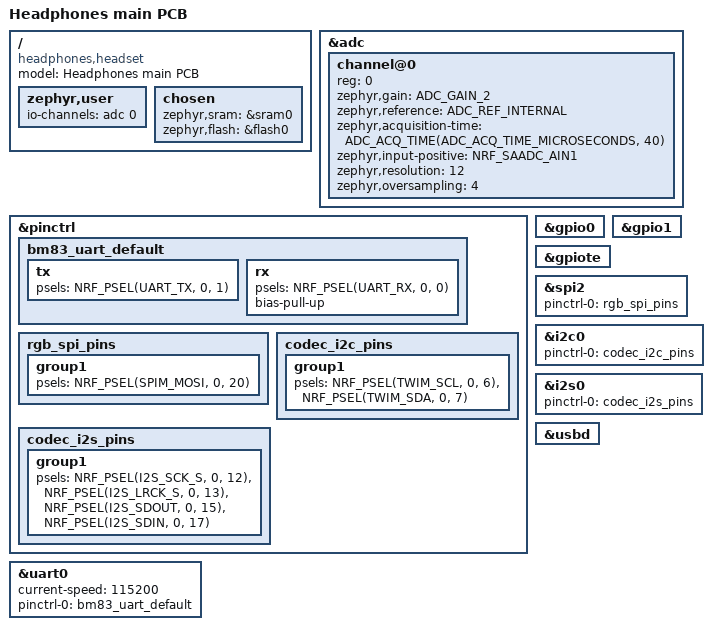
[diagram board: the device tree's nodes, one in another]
/dts-v1/;

#include <nordic/nrf52840_qiaa.dtsi>
#include <zephyr/dt-bindings/adc/adc.h>
#include <zephyr/dt-bindings/adc/nrf-saadc.h>
#include <zephyr/dt-bindings/pinctrl/nrf-pinctrl.h>

/ {
    model = "Headphones main PCB";
    compatible = "headphones,headset";

    zephyr,user {
        io-channels = <&adc 0>;
    };

    chosen {
        zephyr,sram = &sram0;
        zephyr,flash = &flash0;
    };
};

&adc {
    status = "okay";
    #address-cells = <1>;
    #size-cells = <0>;

    channel@0 {
        reg = <0>;
        zephyr,gain = "ADC_GAIN_2";
        zephyr,reference = "ADC_REF_INTERNAL";
        zephyr,acquisition-time = <ADC_ACQ_TIME(ADC_ACQ_TIME_MICROSECONDS, 40)>;
        zephyr,input-positive = <NRF_SAADC_AIN1>;
        zephyr,resolution = <12>;
        zephyr,oversampling = <4>;
    };
};

&pinctrl {
    bm83_uart_default: bm83_uart_default {
        tx {
            psels = <NRF_PSEL(UART_TX, 0, 1)>;
        };
        rx {
            psels = <NRF_PSEL(UART_RX, 0, 0)>;
            bias-pull-up;
        };
    };
    rgb_spi_pins: rgb_spi_pins {
        group1 {
            psels = <NRF_PSEL(SPIM_MOSI, 0, 20)>;
        };
    };
    codec_i2c_pins: codec_i2c_pins {
        group1 {
            psels = <NRF_PSEL(TWIM_SCL, 0, 6)>,
                    <NRF_PSEL(TWIM_SDA, 0, 7)>;
        };
    };
    codec_i2s_pins: codec_i2s_pins {
        group1 {
            psels = <NRF_PSEL(I2S_SCK_S, 0, 12)>,
                    <NRF_PSEL(I2S_LRCK_S, 0, 13)>,
                    <NRF_PSEL(I2S_SDOUT, 0, 15)>,
                    <NRF_PSEL(I2S_SDIN, 0, 17)>;
        };
    };
};

&gpio0 {
    status = "okay";
};

&gpio1 {
    status = "okay";
};

&gpiote {
    status = "okay";
};

&uart0 {
    status = "okay";
    current-speed = <115200>;
    pinctrl-0 = <&bm83_uart_default>;
    pinctrl-names = "default";
};

&spi2 {
    status = "okay";
    pinctrl-0 = <&rgb_spi_pins>;
    pinctrl-names = "default";
};

&i2c0 {
    status = "okay";
    pinctrl-0 = <&codec_i2c_pins>;
    pinctrl-names = "default";
};

&i2s0 {
    status = "okay";
    pinctrl-0 = <&codec_i2s_pins>;
    pinctrl-names = "default";
};

zephyr_udc0: &usbd {
    status = "okay";
};
